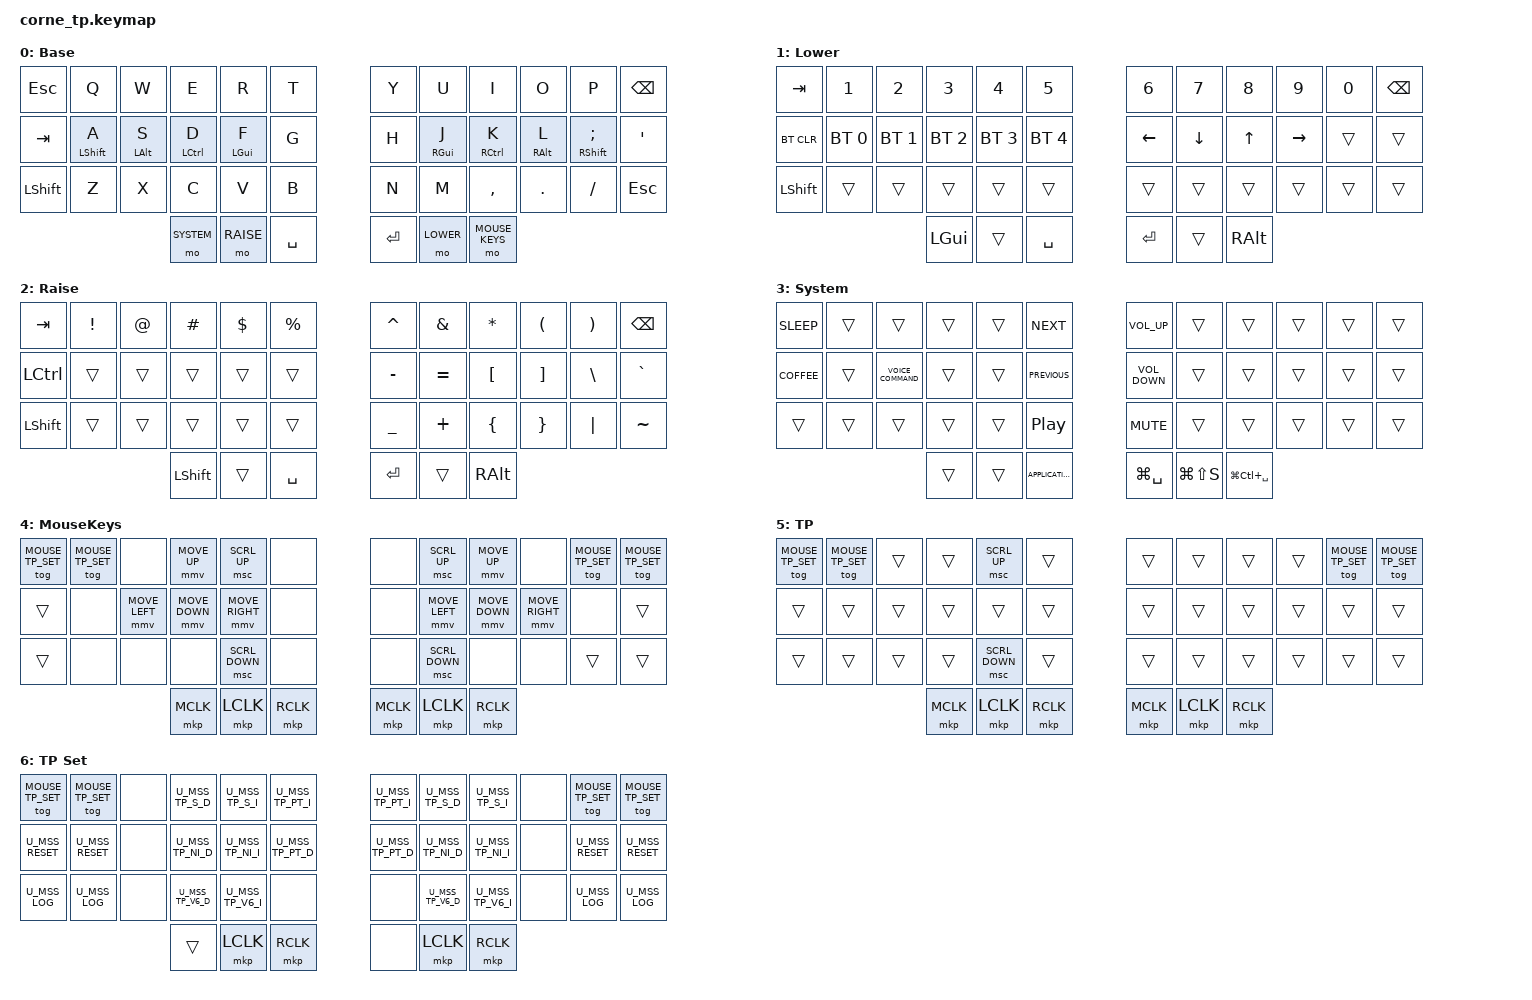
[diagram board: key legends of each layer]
/*
 * Corne TP Keymap with PS/2 TrackPoint support
 * 42 keys: 3 rows x 6 columns per half + 3 thumb keys per half
 *
 * Copyright (c) 2020 The ZMK Contributors
 *
 * SPDX-License-Identifier: MIT
 */

#include <behaviors.dtsi>
#include <dt-bindings/zmk/keys.h>
#include <dt-bindings/zmk/bt.h>

#define BASE 0
#define LOWER 1
#define RAISE 2
#define SYSTEM 3
#define MOUSE_KEYS 4
#define MOUSE_TP 5
#define MOUSE_TP_SET 6

/*
 * Feature flags - comment out to disable mouse features
 */
#define HAS_MOUSE_KEYS
#define HAS_MOUSE_TP

#ifdef HAS_MOUSE_KEYS
  #include <dt-bindings/zmk/mouse.h>
  #include <behaviors/mouse_keys.dtsi>
#endif

#ifdef HAS_MOUSE_TP
  #include "include/mouse_tp.dtsi"
#endif

/*
 * Layer toggle helpers based on enabled features
 */
#ifdef HAS_MOUSE_KEYS
  #define U_THUMB_INNER &mo MOUSE_KEYS
#else
  #define U_THUMB_INNER &none
#endif

#ifdef HAS_MOUSE_TP
  #define U_TOG_TP_SET &tog MOUSE_TP_SET
#else
  #define U_TOG_TP_SET &none
#endif

/*
 * Home Row Mods - Timeless configuration
 * Left:  A=Shift, S=Alt,   D=Control, F=GUI
 * Right: J=GUI,  K=Control, L=Alt,    ;=Shift
 */
/ {
    behaviors {
        hml: home_row_mod_left {
            compatible = "zmk,behavior-hold-tap";
            #binding-cells = <2>;
            flavor = "balanced";
            require-prior-idle-ms = <150>;
            tapping-term-ms = <280>;
            quick-tap-ms = <175>;
            bindings = <&kp>, <&kp>;
            hold-trigger-key-positions = <
                6  7  8  9 10 11   // Y U I O P BSPC
                18 19 20 21 22 23  // H J K L ;  '
                30 31 32 33 34 35  // N M , . / ESC
                39 40 41 42        // RET RET LOWER MOUSE
            >;
            hold-trigger-on-release;
        };
        hmr: home_row_mod_right {
            compatible = "zmk,behavior-hold-tap";
            #binding-cells = <2>;
            flavor = "balanced";
            require-prior-idle-ms = <150>;
            tapping-term-ms = <280>;
            quick-tap-ms = <175>;
            bindings = <&kp>, <&kp>;
            hold-trigger-key-positions = <
                0  1  2  3  4  5   // ESC Q W E R T
                12 13 14 15 16 17  // TAB A S D F G
                24 25 26 27 28 29  // LSHFT Z X C V B
                36 37 38           // SYSTEM RAISE SPACE
            >;
            hold-trigger-on-release;
        };
    };

    keymap {
        compatible = "zmk,keymap";

        Base_layer {
            display-name = "Base";
            bindings = <
// |  ESC |  Q  |  W  |  E  |  R  |  T  |   |  Y  |  U   |  I  |  O  |  P  | BKSP |
// |  TAB | SHFT| ALT |CTRL | GUI |  G  |   |  H  | GUI  |CTRL | ALT  | SHFT |  '   |
// | SHFT |  Z  |  X  |  C  |  V  |  B  |   |  N  |  M   |  ,  |  .  |  /  | ESC  |
//                 | SYS | RSE | SPC |   | RET | RET  | LWR |
 &kp ESC   &kp Q &kp W &kp E &kp R &kp T   &kp Y &kp U  &kp I     &kp O   &kp P    &kp BSPC
 &kp TAB &hml LSHIFT A &hml LALT S &hml LCTRL D &hml LGUI F &kp G   &kp H &hmr RGUI J  &hmr RCTRL K &hmr RALT L   &hmr RSHIFT SEMI &kp SQT
 &kp LSHFT &kp Z &kp X &kp C &kp V &kp B   &kp N &kp M  &kp COMMA &kp DOT &kp FSLH &kp ESC
                    &mo SYSTEM &mo RAISE &kp SPACE  &kp RET &mo LOWER U_THUMB_INNER
            >;
        };

        Lower_layer {
            display-name = "Lower";
            // -----------------------------------------------------------------------------------------
            // |  TAB |  1  |  2  |  3  |  4  |  5  |   |  6  |  7  |  8  |  9  |  0  | BSPC |
            // | BTCLR| BT1 | BT2 | BT3 | BT4 | BT5 |   | LFT | DWN |  UP | RGT |     |      |
            // | SHFT |     |     |     |     |     |   |     |     |     |     |     |      |
            //                    | GUI |     | SPC |   | ENT |     | ALT |

            bindings = <
&kp TAB     &kp N1        &kp N2        &kp N3        &kp N4        &kp N5          &kp N6    &kp N7    &kp N8    &kp N9     &kp N0  &kp BSPC
&bt BT_CLR  &bt BT_SEL 0  &bt BT_SEL 1  &bt BT_SEL 2  &bt BT_SEL 3  &bt BT_SEL 4    &kp LEFT  &kp DOWN  &kp UP    &kp RIGHT  &trans  &trans
&kp LSHFT   &trans        &trans        &trans        &trans        &trans          &trans    &trans    &trans    &trans     &trans  &trans
                                        &kp LGUI      &trans        &kp SPACE       &kp RET   &trans    &kp RALT
            >;
        };

        Raise_layer {
            display-name = "Raise";
            // -----------------------------------------------------------------------------------------
            // |  TAB |  !  |  @  |  #  |  $  |  %  |   |  ^  |  &  |  *  |  (  |  )  | BSPC |
            // | CTRL |     |     |     |     |     |   |  -  |  =  |  [  |  ]  |  \  |  `   |
            // | SHFT |     |     |     |     |     |   |  _  |  +  |  {  |  }  | "|" |  ~   |
            //                    | GUI |     | SPC |   | ENT |     | ALT |

            bindings = <
&kp TAB    &kp EXCL  &kp AT  &kp HASH        &kp DLLR  &kp PRCNT    &kp CARET  &kp AMPS   &kp ASTRK  &kp LPAR  &kp RPAR  &kp BSPC
&kp LCTRL  &trans    &trans  &trans          &trans    &trans       &kp MINUS  &kp EQUAL  &kp LBKT   &kp RBKT  &kp BSLH  &kp GRAVE
&kp LSHFT  &trans    &trans  &trans          &trans    &trans       &kp UNDER  &kp PLUS   &kp LBRC   &kp RBRC  &kp PIPE  &kp TILDE
                             &kp LEFT_SHIFT  &trans    &kp SPACE    &kp RET    &trans     &kp RALT
            >;
        };

        System_layer {
            display-name = "System";
            bindings = <
&kp K_SLEEP   &trans  &trans               &trans  &trans  &kp C_NEXT           &kp C_VOLUME_UP    &trans         &trans             &trans  &trans  &trans
&kp K_COFFEE  &trans  &kp C_VOICE_COMMAND  &trans  &trans  &kp C_PREVIOUS       &kp C_VOLUME_DOWN  &trans         &trans             &trans  &trans  &trans
&trans        &trans  &trans               &trans  &trans  &kp C_PLAY_PAUSE     &kp K_MUTE         &trans         &trans             &trans  &trans  &trans
                                           &trans  &trans  &kp K_APPLICATION    &kp LG(SPACE)      &kp LG(LS(S))  &kp LG(LC(SPACE))
            >;
        };

#ifdef HAS_MOUSE_KEYS
        MouseKeys_layer {
            display-name = "MouseKeys";
            bindings = <
// |  1  |     |     | UP | SCR UP |     |   |     | SCR UP | UP |     |  1  |
// |     |     | LFT | DWN| RGHT |     |   |     | LFT | DWN | RGHT |     |     |
// |     |     |     |    | SCR DWN|     |   |     | SCR DWN |    |     |     |     |
//                 | MCLK | LCLK | RCLK |   | MCLK | LCLK | RCLK |
 U_TOG_TP_SET U_TOG_TP_SET       &none    &mmv MOVE_UP   &msc SCRL_UP  &none        &none   &msc SCRL_UP  &mmv MOVE_UP  &none  U_TOG_TP_SET U_TOG_TP_SET
 &trans       &none             &mmv MOVE_LEFT &mmv MOVE_DOWN &mmv MOVE_RIGHT &none    &none   &mmv MOVE_LEFT &mmv MOVE_DOWN &mmv MOVE_RIGHT &none  &trans
 &trans       &none             &none          &none          &msc SCRL_DOWN &none    &none   &msc SCRL_DOWN &none          &none          &trans &trans
                                  &mkp MCLK    &mkp LCLK     &mkp RCLK    &mkp MCLK    &mkp LCLK    &mkp RCLK
            >;
        };
#endif

#ifdef HAS_MOUSE_TP
        // Auto-activated when TrackPoint moves (configured in mouse_tp.dtsi)
        MouseTP_layer {
            display-name = "TP";
            bindings = <
// |  SET | SET |     | UP | SCR UP |     |   |     | SCR UP | UP |     | SET | SET |
// |     |     | LFT | DWN| RGHT |     |   |     | LFT | DWN | RGHT |     |     |
// |     |     |     |    | SCR DWN|     |   |     | SCR DWN |    |     |     |     |
//                 | MCLK | LCLK | RCLK |   | MCLK | LCLK | RCLK |
 U_TOG_TP_SET U_TOG_TP_SET &trans &trans &msc SCRL_UP &trans    &trans  &trans  &trans  &trans U_TOG_TP_SET U_TOG_TP_SET
 &trans &trans &trans &trans &trans &trans    &trans  &trans  &trans  &trans  &trans &trans
 &trans &trans &trans &trans &msc SCRL_DOWN &trans    &trans  &trans  &trans  &trans  &trans &trans
                   &mkp MCLK &mkp LCLK &mkp RCLK    &mkp MCLK &mkp LCLK &mkp RCLK
            >;
        };

        // TrackPoint settings layer
        MouseSettings_layer {
            display-name = "TP Set";
            bindings = <
// |  SET | SET |     | Sens- | Sens+ | PTS+ |   | PTS+ | Sens- | Sens+ |     | SET | SET |
// |RESET |RESET|     | Inert-| Inert+| PTS- |   | PTS- | Inert-| Inert+|     |RESET |RESET|
// |  LOG | LOG |     | Val6- | Val6+ |     |   |     | Val6- | Val6+ |     |  LOG | LOG |
//                 |     | LCLK | RCLK |   |     | LCLK | RCLK |
 U_TOG_TP_SET U_TOG_TP_SET &none U_MSS_TP_S_D U_MSS_TP_S_I U_MSS_TP_PT_I    U_MSS_TP_PT_I U_MSS_TP_S_D U_MSS_TP_S_I &none U_TOG_TP_SET U_TOG_TP_SET
 U_MSS_RESET  U_MSS_RESET   &none U_MSS_TP_NI_D U_MSS_TP_NI_I U_MSS_TP_PT_D    U_MSS_TP_PT_D U_MSS_TP_NI_D U_MSS_TP_NI_I &none U_MSS_RESET U_MSS_RESET
 U_MSS_LOG    U_MSS_LOG     &none U_MSS_TP_V6_D U_MSS_TP_V6_I &none          &none  U_MSS_TP_V6_D U_MSS_TP_V6_I &none  U_MSS_LOG   U_MSS_LOG
                             &trans &mkp LCLK &mkp RCLK    &none &mkp LCLK &mkp RCLK
            >;
        };
#endif
    };
};
